# STM32L052 register map
File version: 1.0
CPU: CM0+ r0p0, little endian, MPU, no FPU, 4 interrupt priority bits
Registers are 32-bit, read-write, reset 0x0 unless marked. A register's access mark holds for its fields unless they carry their own. Offsets are from the block's base; [hi:lo] are bit positions.

## RCC — Reset and clock control
Base 0x40021000
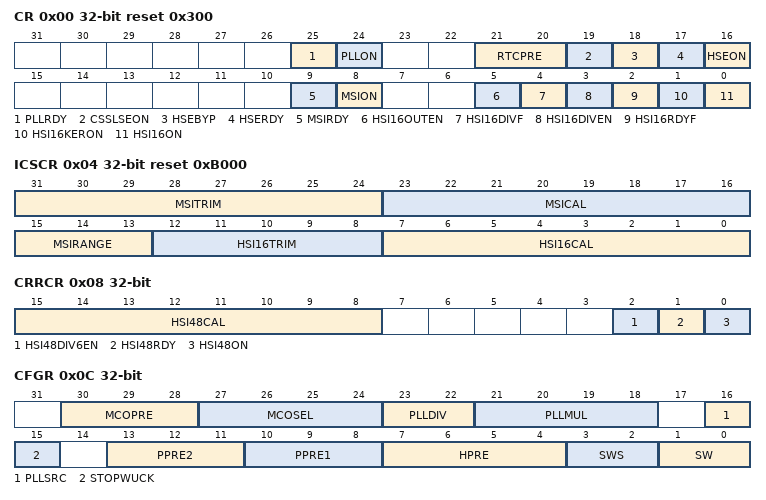
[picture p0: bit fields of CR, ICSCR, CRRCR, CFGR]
0x00 CR access per field reset 0x300 — Clock control register
  [25] PLLRDY ro — PLL clock ready flag
  [24] PLLON rw — PLL enable bit
  [21:20] RTCPRE rw — TC/LCD prescaler
  [19] CSSLSEON rw — Clock security system on HSE enable bit
  [18] HSEBYP rw — HSE clock bypass bit
  [17] HSERDY ro — HSE clock ready flag
  [16] HSEON rw — HSE clock enable bit
  [9] MSIRDY ro — MSI clock ready flag
  [8] MSION rw — MSI clock enable bit
  [5] HSI16OUTEN rw — 16 MHz high-speed internal clock output enable
  [4] HSI16DIVF ro
  [3] HSI16DIVEN rw
  [2] HSI16RDYF rw — Internal high-speed clock ready flag
  [1] HSI16KERON ro — High-speed internal clock enable bit for some IP kernels
  [0] HSI16ON rw — 16 MHz high-speed internal clock enable
0x04 ICSCR access per field reset 0xB000 — Internal clock sources calibration register
  [31:24] MSITRIM rw — MSI clock trimming
  [23:16] MSICAL ro — MSI clock calibration
  [15:13] MSIRANGE rw — MSI clock ranges
  [12:8] HSI16TRIM rw — High speed internal clock trimming
  [7:0] HSI16CAL ro — nternal high speed clock calibration
0x08 CRRCR access per field — Clock recovery RC register
  [15:8] HSI48CAL ro — 48 MHz HSI clock calibration
  [2] HSI48DIV6EN rw — 48 MHz HSI clock divided by 6 output enable
  [1] HSI48RDY ro — 48MHz HSI clock ready flag
  [0] HSI48ON rw — 48MHz HSI clock enable bit
0x0C CFGR access per field — Clock configuration register
  [30:28] MCOPRE rw — Microcontroller clock output prescaler
  [27:24] MCOSEL rw — Microcontroller clock output selection
  [23:22] PLLDIV rw — PLL output division
  [21:18] PLLMUL rw — PLL multiplication factor
  [16] PLLSRC rw — PLL entry clock source
  [15] STOPWUCK rw — Wake-up from stop clock selection
  [13:11] PPRE2 rw — APB high-speed prescaler (APB2)
  [10:8] PPRE1 rw — APB low-speed prescaler (APB1)
  [7:4] HPRE rw — AHB prescaler
  [3:2] SWS ro — System clock switch status
  [1:0] SW rw — System clock switch
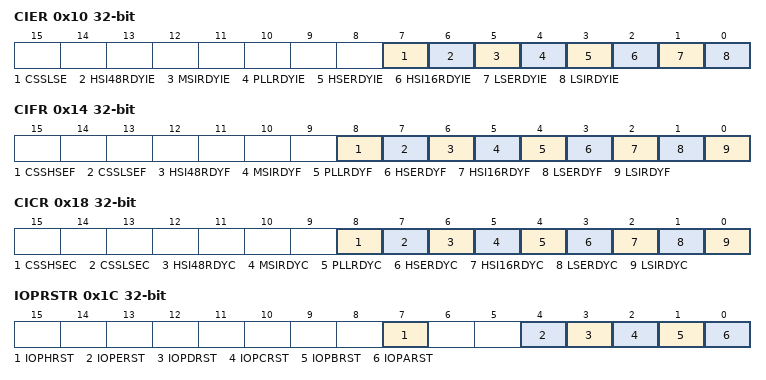
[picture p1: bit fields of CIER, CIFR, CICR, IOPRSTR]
0x10 CIER ro — Clock interrupt enable register
  [7] CSSLSE — LSE CSS interrupt flag
  [6] HSI48RDYIE — HSI48 ready interrupt flag
  [5] MSIRDYIE — MSI ready interrupt flag
  [4] PLLRDYIE — PLL ready interrupt flag
  [3] HSERDYIE — HSE ready interrupt flag
  [2] HSI16RDYIE — HSI16 ready interrupt flag
  [1] LSERDYIE — LSE ready interrupt flag
  [0] LSIRDYIE — LSI ready interrupt flag
0x14 CIFR ro — Clock interrupt flag register
  [8] CSSHSEF — Clock Security System Interrupt flag
  [7] CSSLSEF — LSE Clock Security System Interrupt flag
  [6] HSI48RDYF — HSI48 ready interrupt flag
  [5] MSIRDYF — MSI ready interrupt flag
  [4] PLLRDYF — PLL ready interrupt flag
  [3] HSERDYF — HSE ready interrupt flag
  [2] HSI16RDYF — HSI16 ready interrupt flag
  [1] LSERDYF — LSE ready interrupt flag
  [0] LSIRDYF — LSI ready interrupt flag
0x18 CICR wo — Clock interrupt clear register
  [8] CSSHSEC — Clock Security System Interrupt clear
  [7] CSSLSEC — LSE Clock Security System Interrupt clear
  [6] HSI48RDYC — HSI48 ready Interrupt clear
  [5] MSIRDYC — MSI ready Interrupt clear
  [4] PLLRDYC — PLL ready Interrupt clear
  [3] HSERDYC — HSE ready Interrupt clear
  [2] HSI16RDYC — HSI16 ready Interrupt clear
  [1] LSERDYC — LSE ready Interrupt clear
  [0] LSIRDYC — LSI ready Interrupt clear
0x1C IOPRSTR — GPIO reset register
  [7] IOPHRST — I/O port H reset
  [4] IOPERST — I/O port E reset
  [3] IOPDRST — I/O port D reset
  [2] IOPCRST — I/O port A reset
  [1] IOPBRST — I/O port B reset
  [0] IOPARST — I/O port A reset
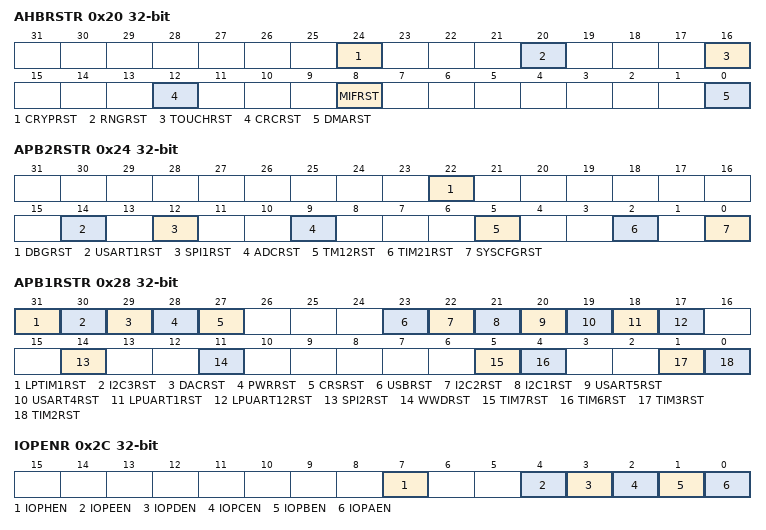
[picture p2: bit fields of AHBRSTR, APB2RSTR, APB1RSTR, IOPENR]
0x20 AHBRSTR — AHB peripheral reset register
  [24] CRYPRST — Crypto module reset
  [20] RNGRST — Random Number Generator module reset
  [16] TOUCHRST — Touch Sensing reset
  [12] CRCRST — Test integration module reset
  [8] MIFRST — Memory interface reset
  [0] DMARST — DMA reset
0x24 APB2RSTR — APB2 peripheral reset register
  [22] DBGRST — DBG reset
  [14] USART1RST — USART1 reset
  [12] SPI1RST — SPI 1 reset
  [9] ADCRST — ADC interface reset
  [5] TM12RST — TIM22 timer reset
  [2] TIM21RST — TIM21 timer reset
  [0] SYSCFGRST — System configuration controller reset
0x28 APB1RSTR — APB1 peripheral reset register
  [31] LPTIM1RST — Low power timer reset
  [30] I2C3RST — I2C3 reset
  [29] DACRST — DAC interface reset
  [28] PWRRST — Power interface reset
  [27] CRSRST — Clock recovery system reset
  [23] USBRST — USB reset
  [22] I2C2RST — I2C2 reset
  [21] I2C1RST — I2C1 reset
  [20] USART5RST — USART5 reset
  [19] USART4RST — USART4 reset
  [18] LPUART1RST — LPUART1 reset
  [17] LPUART12RST — UART2 reset
  [14] SPI2RST — SPI2 reset
  [11] WWDRST — Window watchdog reset
  [5] TIM7RST — Timer 7 reset
  [4] TIM6RST — Timer 6 reset
  [1] TIM3RST — Timer3 reset
  [0] TIM2RST — Timer2 reset
0x2C IOPENR — GPIO clock enable register
  [7] IOPHEN — I/O port H clock enable bit
  [4] IOPEEN — I/O port E clock enable bit
  [3] IOPDEN — I/O port D clock enable bit
  [2] IOPCEN — IO port A clock enable bit
  [1] IOPBEN — IO port B clock enable bit
  [0] IOPAEN — IO port A clock enable bit
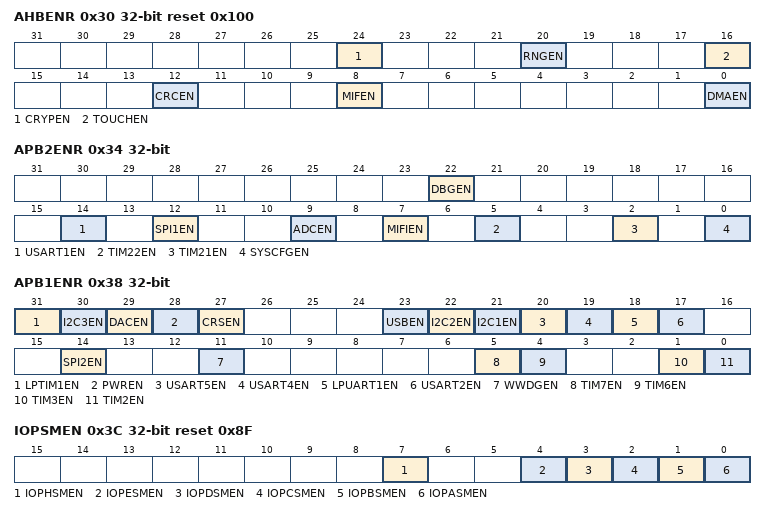
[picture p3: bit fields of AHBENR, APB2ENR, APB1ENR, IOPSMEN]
0x30 AHBENR reset 0x100 — AHB peripheral clock enable register
  [24] CRYPEN — Crypto clock enable bit
  [20] RNGEN — Random Number Generator clock enable bit
  [16] TOUCHEN — Touch Sensing clock enable bit
  [12] CRCEN — CRC clock enable bit
  [8] MIFEN — NVM interface clock enable bit
  [0] DMAEN — DMA clock enable bit
0x34 APB2ENR — APB2 peripheral clock enable register
  [22] DBGEN — DBG clock enable bit
  [14] USART1EN — USART1 clock enable bit
  [12] SPI1EN — SPI1 clock enable bit
  [9] ADCEN — ADC clock enable bit
  [7] MIFIEN — MiFaRe Firewall clock enable bit
  [5] TIM22EN — TIM22 timer clock enable bit
  [2] TIM21EN — TIM21 timer clock enable bit
  [0] SYSCFGEN — System configuration controller clock enable bit
0x38 APB1ENR — APB1 peripheral clock enable register
  [31] LPTIM1EN — Low power timer clock enable bit
  [30] I2C3EN — I2C3 clock enable bit
  [29] DACEN — DAC interface clock enable bit
  [28] PWREN — Power interface clock enable bit
  [27] CRSEN — Clock recovery system clock enable bit
  [23] USBEN — USB clock enable bit
  [22] I2C2EN — I2C2 clock enable bit
  [21] I2C1EN — I2C1 clock enable bit
  [20] USART5EN — USART5 clock enable bit
  [19] USART4EN — USART4 clock enable bit
  [18] LPUART1EN — LPUART1 clock enable bit
  [17] USART2EN — UART2 clock enable bit
  [14] SPI2EN — SPI2 clock enable bit
  [11] WWDGEN — Window watchdog clock enable bit
  [5] TIM7EN — Timer 7 clock enable bit
  [4] TIM6EN — Timer 6 clock enable bit
  [1] TIM3EN — Timer3 clock enable bit
  [0] TIM2EN — Timer2 clock enable bit
0x3C IOPSMEN reset 0x8F — GPIO clock enable in sleep mode register
  [7] IOPHSMEN
  [4] IOPESMEN — Port E clock enable during Sleep mode bit
  [3] IOPDSMEN
  [2] IOPCSMEN
  [1] IOPBSMEN
  [0] IOPASMEN
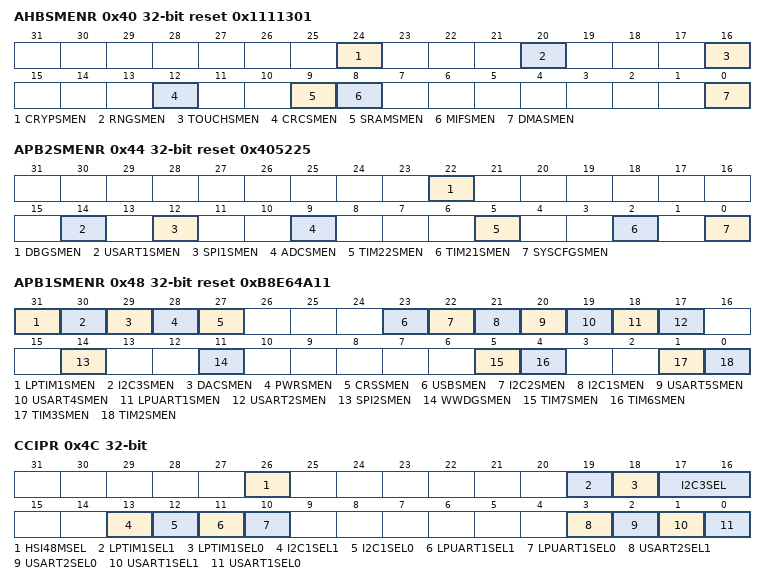
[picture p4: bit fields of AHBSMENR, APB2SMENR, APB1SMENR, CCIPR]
0x40 AHBSMENR reset 0x1111301 — AHB peripheral clock enable in sleep mode register
  [24] CRYPSMEN — Crypto clock enable during sleep mode bit
  [20] RNGSMEN — Random Number Generator clock enable during sleep mode bit
  [16] TOUCHSMEN — Touch Sensing clock enable during sleep mode bit
  [12] CRCSMEN — CRC clock enable during sleep mode bit
  [9] SRAMSMEN — SRAM interface clock enable during sleep mode bit
  [8] MIFSMEN — NVM interface clock enable during sleep mode bit
  [0] DMASMEN — DMA clock enable during sleep mode bit
0x44 APB2SMENR reset 0x405225 — APB2 peripheral clock enable in sleep mode register
  [22] DBGSMEN — DBG clock enable during sleep mode bit
  [14] USART1SMEN — USART1 clock enable during sleep mode bit
  [12] SPI1SMEN — SPI1 clock enable during sleep mode bit
  [9] ADCSMEN — ADC clock enable during sleep mode bit
  [5] TIM22SMEN — TIM22 timer clock enable during sleep mode bit
  [2] TIM21SMEN — TIM21 timer clock enable during sleep mode bit
  [0] SYSCFGSMEN — System configuration controller clock enable during sleep mode bit
0x48 APB1SMENR reset 0xB8E64A11 — APB1 peripheral clock enable in sleep mode register
  [31] LPTIM1SMEN — Low power timer clock enable during sleep mode bit
  [30] I2C3SMEN — 2C3 clock enable during Sleep mode bit
  [29] DACSMEN — DAC interface clock enable during sleep mode bit
  [28] PWRSMEN — Power interface clock enable during sleep mode bit
  [27] CRSSMEN — Clock recovery system clock enable during sleep mode bit
  [23] USBSMEN — USB clock enable during sleep mode bit
  [22] I2C2SMEN — I2C2 clock enable during sleep mode bit
  [21] I2C1SMEN — I2C1 clock enable during sleep mode bit
  [20] USART5SMEN — USART5 clock enable during Sleep mode bit
  [19] USART4SMEN — USART4 clock enable during Sleep mode bit
  [18] LPUART1SMEN — LPUART1 clock enable during sleep mode bit
  [17] USART2SMEN — UART2 clock enable during sleep mode bit
  [14] SPI2SMEN — SPI2 clock enable during sleep mode bit
  [11] WWDGSMEN — Window watchdog clock enable during sleep mode bit
  [5] TIM7SMEN — Timer 7 clock enable during Sleep mode bit
  [4] TIM6SMEN — Timer 6 clock enable during sleep mode bit
  [1] TIM3SMEN — Timer3 clock enable during Sleep mode bit
  [0] TIM2SMEN — Timer2 clock enable during sleep mode bit
0x4C CCIPR — Clock configuration register
  [26] HSI48MSEL — 48 MHz HSI48 clock source selection bit
  [19] LPTIM1SEL1 — Low Power Timer clock source selection bits
  [18] LPTIM1SEL0
  [17:16] I2C3SEL — I2C3 clock source selection bits
  [13] I2C1SEL1 — I2C1 clock source selection bits
  [12] I2C1SEL0
  [11] LPUART1SEL1 — LPUART1 clock source selection bits
  [10] LPUART1SEL0
  [3] USART2SEL1 — USART2 clock source selection bits
  [2] USART2SEL0
  [1] USART1SEL1 — USART1 clock source selection bits
  [0] USART1SEL0
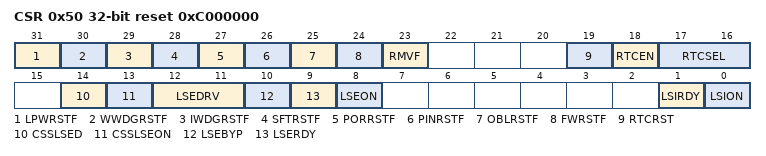
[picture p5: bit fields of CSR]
0x50 CSR access per field reset 0xC000000 — Control and status register
  [31] LPWRSTF ro — Low-power reset flag
  [30] WWDGRSTF ro — Window watchdog reset flag
  [29] IWDGRSTF ro — Independent watchdog reset flag
  [28] SFTRSTF ro — Software reset flag
  [27] PORRSTF ro — POR/PDR reset flag
  [26] PINRSTF ro — PIN reset flag
  [25] OBLRSTF ro
  [24] FWRSTF ro — : Firewall reset flag
  [23] RMVF rw — Remove reset flag
  [19] RTCRST rw — RTC software reset bit
  [18] RTCEN rw — RTC clock enable bit
  [17:16] RTCSEL rw — RTC and LCD clock source selection bits
  [14] CSSLSED ro — CSS on LSE failure detection flag
  [13] CSSLSEON rw
  [12:11] LSEDRV rw
  [10] LSEBYP rw — External low-speed oscillator bypass bit
  [9] LSERDY ro — External low-speed oscillator ready bit
  [8] LSEON rw — External low-speed oscillator enable bit
  [1] LSIRDY ro — Internal low-speed oscillator ready bit
  [0] LSION rw — Internal low-speed oscillator enable
